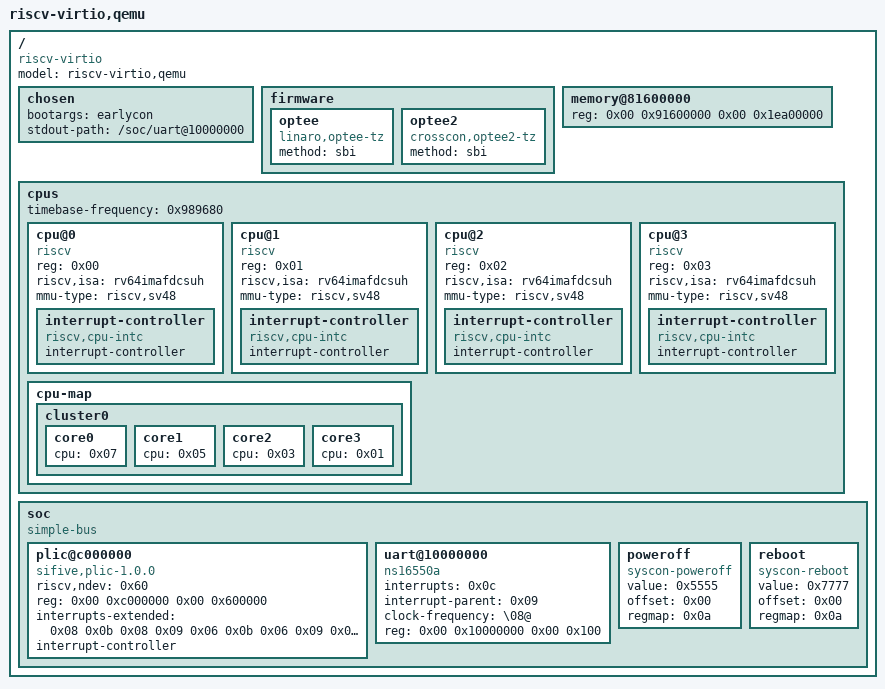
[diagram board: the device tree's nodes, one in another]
/dts-v1/;

/ {
	#address-cells = <0x02>;
	#size-cells = <0x02>;
	compatible = "riscv-virtio";
	model = "riscv-virtio,qemu";

	chosen {
		bootargs = "earlycon";
		stdout-path = "/soc/uart@10000000";
	};

	firmware {
		optee {
			compatible = "linaro,optee-tz";
			method = "sbi";
		};
                optee2 {
			compatible = "crosscon,optee2-tz";
			method = "sbi";
		};
	};


	memory@81600000 {
		device_type = "memory";
		reg = <0x00 0x91600000 0x00 0x1ea00000>;
	};

	cpus {
		#address-cells = <0x01>;
		#size-cells = <0x00>;
		timebase-frequency = <0x989680>;

		cpu@0 {
			phandle = <0x07>;
			device_type = "cpu";
			reg = <0x00>;
			status = "okay";
			compatible = "riscv";
			riscv,isa = "rv64imafdcsuh";
			mmu-type = "riscv,sv48";

			interrupt-controller {
				#interrupt-cells = <0x01>;
				interrupt-controller;
				compatible = "riscv,cpu-intc";
				phandle = <0x08>;
			};
		};

		cpu@1 {
			phandle = <0x05>;
			device_type = "cpu";
			reg = <0x01>;
			status = "okay";
			compatible = "riscv";
			riscv,isa = "rv64imafdcsuh";
			mmu-type = "riscv,sv48";

			interrupt-controller {
				#interrupt-cells = <0x01>;
				interrupt-controller;
				compatible = "riscv,cpu-intc";
				phandle = <0x06>;
			};
		};

		cpu@2 {
			phandle = <0x03>;
			device_type = "cpu";
			reg = <0x02>;
			status = "okay";
			compatible = "riscv";
			riscv,isa = "rv64imafdcsuh";
			mmu-type = "riscv,sv48";

			interrupt-controller {
				#interrupt-cells = <0x01>;
				interrupt-controller;
				compatible = "riscv,cpu-intc";
				phandle = <0x04>;
			};
		};

		cpu@3 {
			phandle = <0x01>;
			device_type = "cpu";
			reg = <0x03>;
			status = "okay";
			compatible = "riscv";
			riscv,isa = "rv64imafdcsuh";
			mmu-type = "riscv,sv48";

			interrupt-controller {
				#interrupt-cells = <0x01>;
				interrupt-controller;
				compatible = "riscv,cpu-intc";
				phandle = <0x02>;
			};
		};

		cpu-map {

			cluster0 {

				core0 {
					cpu = <0x07>;
				};

				core1 {
					cpu = <0x05>;
				};

				core2 {
					cpu = <0x03>;
				};

				core3 {
					cpu = <0x01>;
				};
			};
		};
	};

	soc {
		#address-cells = <0x02>;
		#size-cells = <0x02>;
		compatible = "simple-bus";
		ranges;

		plic@c000000 {
			phandle = <0x09>;
			riscv,ndev = <0x60>;
			reg = <0x00 0xc000000 0x00 0x600000>;
			interrupts-extended = <0x08 0x0b 0x08 0x09 0x06 0x0b 0x06 0x09 0x04 0x0b 0x04 0x09 0x02 0x0b 0x02 0x09>;
			interrupt-controller;
			compatible = "sifive,plic-1.0.0\0riscv,plic0";
			#interrupt-cells = <0x01>;
		};

		/* rtc@101000 { */
		/* 	interrupts = <0x0b>; */
		/* 	interrupt-parent = <0x09>; */
		/* 	reg = <0x00 0x101000 0x00 0x1000>; */
		/* 	compatible = "google,goldfish-rtc"; */
		/* }; */

		uart@10000000 {
			interrupts = <0x0c>;
			interrupt-parent = <0x09>;
			clock-frequency = "\08@";
			reg = <0x00 0x10000000 0x00 0x100>;
			compatible = "ns16550a";
		};

		poweroff {
			value = <0x5555>;
			offset = <0x00>;
			regmap = <0x0a>;
			compatible = "syscon-poweroff";
		};

		reboot {
			value = <0x7777>;
			offset = <0x00>;
			regmap = <0x0a>;
			compatible = "syscon-reboot";
		};
	};
};


